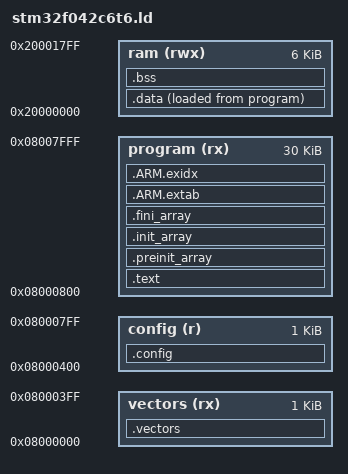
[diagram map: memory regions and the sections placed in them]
EXTERN(vector_table)
ENTRY(reset_handler)
MEMORY
{
 ram (rwx) : ORIGIN = 0x20000000, LENGTH = 6K
 vectors (rx) : ORIGIN = 0x08000000, LENGTH = 1K
 config (r) : ORIGIN = 0x08000400, LENGTH = 1K
 program (rx) : ORIGIN = 0x08000800, LENGTH = 30K
}
SECTIONS
{
 .vectors : {
  *(.vectors)
  . = ALIGN(4);
 } >vectors
 .config : {
  *(.config)
  . = ALIGN(4);
 } >config
 .text : {
  *(.text*)
  . = ALIGN(4);
  *(.rodata*)
  . = ALIGN(4);
 } >program
 .preinit_array : {
  . = ALIGN(4);
  __preinit_array_start = .;
  KEEP (*(.preinit_array))
  __preinit_array_end = .;
 } >program
 .init_array : {
  . = ALIGN(4);
  __init_array_start = .;
  KEEP (*(SORT(.init_array.*)))
  KEEP (*(.init_array))
  __init_array_end = .;
 } >program
 .fini_array : {
  . = ALIGN(4);
  __fini_array_start = .;
  KEEP (*(.fini_array))
  KEEP (*(SORT(.fini_array.*)))
  __fini_array_end = .;
 } >program
 .ARM.extab : {
  *(.ARM.extab*)
 } >program
 .ARM.exidx : {
  __exidx_start = .;
  *(.ARM.exidx*)
  __exidx_end = .;
 } >program
 . = ALIGN(4);
 _etext = .;
 .data : {
  _data = .;
  *(.data*)
  . = ALIGN(4);
  _edata = .;
 } >ram AT >program
 _data_loadaddr = LOADADDR(.data);
 .bss : {
  *(.bss*)
  *(COMMON)
  . = ALIGN(4);
  _ebss = .;
 } >ram
 /DISCARD/ : { *(.eh_frame) }
 . = ALIGN(4);
 end = .;
}
PROVIDE(_stack = ORIGIN(ram) + LENGTH(ram));
